AUTOSAR XML (schema 00044)
package /E40_Platform_System_SystemPackage/Components
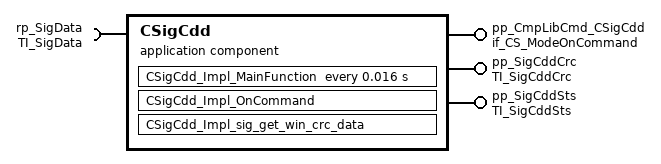
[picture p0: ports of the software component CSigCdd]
  application sw component type CSigCdd
    provide port pp_CmpLibCmd_CSigCdd: server-com-spec{operation=Impl_OnCommand, queue-length=1}, provided-interface=if_CS_ModeOnCommand
    provide port pp_SigCddCrc: server-com-spec{operation=Impl_sig_get_win_crc_data, queue-length=1}, provided-interface=TI_SigCddCrc
    provide port pp_SigCddSts: nonqueued-sender-com-spec{data-element=win_violation_output, init-value=constant-reference=CSigCddwin_violation_outputValue0}, provided-interface=TI_SigCddSts
    require port rp_SigData: nonqueued-receiver-com-spec{data-element=sig0_port, init-value=constant-reference=CSigCddsig0_portValue0}, required-interface=TI_SigData
    behavior IB_CSigCdd
      timing event TECSigCdd_Impl_MainFunction: start-on-event=CSigCdd_Impl_MainFunction, period=0.016
      operation invoked event OIE_pp_CmpLibCmd_CSigCdd_CSigCdd_Impl_OnCommandTrigByImpl_OnCommand: start-on-event=CSigCdd_Impl_OnCommand, operation=pp_CmpLibCmd_CSigCdd.Impl_OnCommand
      operation invoked event OIE_pp_SigCddCrc_CSigCdd_Impl_sig_get_win_crc_dataTrigByImpl_sig_get_win_crc_data: start-on-event=CSigCdd_Impl_sig_get_win_crc_data, operation=pp_SigCddCrc.Impl_sig_get_win_crc_data
      port-api-options:
        enable-take-address=false, indirect-api=false, port=pp_CmpLibCmd_CSigCdd
        enable-take-address=false, indirect-api=false, port=pp_SigCddCrc
        enable-take-address=false, indirect-api=false, port=pp_SigCddSts
        enable-take-address=false, indirect-api=false, port=rp_SigData
      runnable CSigCdd_Impl_MainFunction: can-be-invoked-concurrently=true
        data-receive-point-by-arguments:
          access DRA_rp_SigData_sig0_port: accessed-variable=rp_SigData.sig0_port
        data-send-points:
          access DWA_pp_SigCddSts_win_violation_output: accessed-variable=pp_SigCddSts.win_violation_output
      runnable CSigCdd_Impl_OnCommand: can-be-invoked-concurrently=true
      runnable CSigCdd_Impl_sig_get_win_crc_data: can-be-invoked-concurrently=true
  swc implementation IMPL_CSigCdd: behavior=IB_CSigCdd
